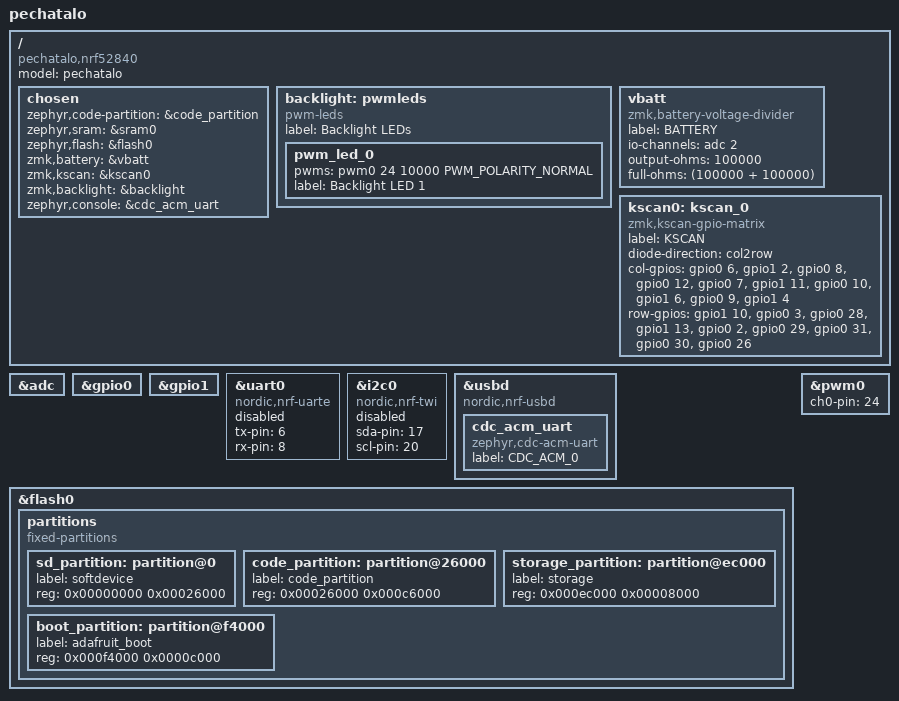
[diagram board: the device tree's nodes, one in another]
/*
 * Copyright (c) 2021 Sascha Ludwig
 *
 * SPDX-License-Identifier: MIT
 */

/dts-v1/;
#include <nordic/nrf52840_qiaa.dtsi>

/ {
	model = "pechatalo";
	compatible = "pechatalo,nrf52840";
	
	chosen {
		zephyr,code-partition = &code_partition;
		zephyr,sram = &sram0;
		zephyr,flash = &flash0;
		zmk,battery = &vbatt;
		zmk,kscan = &kscan0;
		zmk,backlight = &backlight;
		zephyr,console = &cdc_acm_uart;
	};
	
	backlight: pwmleds {
        compatible = "pwm-leds";
        label = "Backlight LEDs";
		pwm_led_0 {
            pwms = <&pwm0 24 10000 PWM_POLARITY_NORMAL>;
            label = "Backlight LED 1";
        };
    };

	vbatt: vbatt {
		compatible = "zmk,battery-voltage-divider";
		label = "BATTERY";
		io-channels = <&adc 2>;
		output-ohms = <100000>;
		full-ohms = <(100000 + 100000)>;
	};

    kscan0: kscan_0 {
		compatible = "zmk,kscan-gpio-matrix";
		label  = "KSCAN";
		diode-direction = "col2row";

		col-gpios
            = <&gpio0 6 GPIO_ACTIVE_HIGH>
            , <&gpio1 2 GPIO_ACTIVE_HIGH>
            , <&gpio0 8 GPIO_ACTIVE_HIGH>
            , <&gpio0 12 GPIO_ACTIVE_HIGH>
            , <&gpio0 7 GPIO_ACTIVE_HIGH>
            , <&gpio1 11 GPIO_ACTIVE_HIGH>
            , <&gpio0 10 GPIO_ACTIVE_HIGH>
            , <&gpio1 6 GPIO_ACTIVE_HIGH>
            , <&gpio0 9 GPIO_ACTIVE_HIGH>
            , <&gpio1 4 GPIO_ACTIVE_HIGH>
            ;

			
		row-gpios
            = <&gpio1 10 (GPIO_ACTIVE_HIGH | GPIO_PULL_DOWN)>
            , <&gpio0 3 (GPIO_ACTIVE_HIGH | GPIO_PULL_DOWN)>
            , <&gpio0 28 (GPIO_ACTIVE_HIGH | GPIO_PULL_DOWN)>
            , <&gpio1 13 (GPIO_ACTIVE_HIGH | GPIO_PULL_DOWN)>
            , <&gpio0 2 (GPIO_ACTIVE_HIGH | GPIO_PULL_DOWN)>
            , <&gpio0 29 (GPIO_ACTIVE_HIGH | GPIO_PULL_DOWN)>
            , <&gpio0 31 (GPIO_ACTIVE_HIGH | GPIO_PULL_DOWN)>
            , <&gpio0 30 (GPIO_ACTIVE_HIGH | GPIO_PULL_DOWN)>
            , <&gpio0 26 (GPIO_ACTIVE_HIGH | GPIO_PULL_DOWN)>
            ;
    };
};

	

&adc {
	status = "okay";
};

&gpio0 {
	status = "okay";
};

&gpio1 {
	status = "okay";
};

&uart0 {
	status = "disabled";
	compatible = "nordic,nrf-uarte";
	tx-pin = <6>;
	rx-pin = <8>;
};

&i2c0 {
	status = "disabled";
	compatible = "nordic,nrf-twi";
	sda-pin = <17>;
	scl-pin = <20>;
};


&usbd {
	compatible = "nordic,nrf-usbd";
	status = "okay";
	cdc_acm_uart: cdc_acm_uart {
		compatible = "zephyr,cdc-acm-uart";
		label = "CDC_ACM_0";
	};
};


&flash0 {
	/*
	 * For more information, see:
	 * http://docs.zephyrproject.org/latest/devices/dts/flash_partitions.html
	 */
	partitions {
		compatible = "fixed-partitions";
		#address-cells = <1>;
		#size-cells = <1>;

		sd_partition: partition@0 {
			label = "softdevice";
			reg = <0x00000000 0x00026000>;
		};
		code_partition: partition@26000 {
			label = "code_partition";
			reg = <0x00026000 0x000c6000>;
		};

		/*
		 * The flash starting at 0x000ec000 and ending at
		 * 0x000f3fff is reserved for use by the application.
		 */

		/*
		 * Storage partition will be used by FCB/LittleFS/NVS
		 * if enabled.
		 */
		storage_partition: partition@ec000 {
			label = "storage";
			reg = <0x000ec000 0x00008000>;
		};

		boot_partition: partition@f4000 {
			label = "adafruit_boot";
			reg = <0x000f4000 0x0000c000>;
		};
	};
};

&pwm0 {
    status = "okay";
	ch0-pin = <24>;
    /* ch0-inverted; */
};
